# WS63 register map
File version: 1.0
CPU: other r0p0, little endian, MPU, FPU, 3 interrupt priority bits
Registers are 32-bit, read-write, reset 0x0 unless marked. A register's access mark holds for its fields unless they carry their own. Offsets are from the block's base; [hi:lo] are bit positions; {n}, {i} and the like mark numbered series.

## IO_CONFIG — IO multiplexing and pad control
Base 0x4400D000
0x00 GPIO_00_SEL — GPIO_00 pin mux select
  [2:0] gpio_00_sel — GPIO_00 pin mux: 0:GPIO_00; 1:PWM0; 2:DIAG[0]; 3:SPI1_CSN; 4:JTAG_TDI
0x04 GPIO_01_SEL — GPIO_01 pin mux select
  [2:0] gpio_01_sel — GPIO_01 pin mux: 0:GPIO_01; 1:PWM1; 2:DIAG[1]; 3:SPI1_IO0; 4:JTAG_MODE; 5:BT_SAMPLE
0x08 GPIO_02_SEL — GPIO_02 pin mux select
  [2:0] gpio_02_sel — GPIO_02 pin mux: 0:GPIO_02; 1:PWM2; 2:DIAG[2]; 3:SPI1_IO3; 4:WIFI_TSF_SYNC; 5:WL_GLP_SYNC_PULSE; 6:BSLE_GLP_SYNC_PULSE
0x0C GPIO_03_SEL — GPIO_03 pin mux select
  [2:0] gpio_03_sel — GPIO_03 pin mux: 0:GPIO_03; 1:PWM3; 2:PMU_32K_TEST; 3:SPI1_IO1; 4:HW_ID[0]; 5:DIAG[3]
0x10 GPIO_04_SEL — GPIO_04 pin mux select
  [2:0] gpio_04_sel — GPIO_04 pin mux: 0:SSI_CLK; 1:PWM4; 2:GPIO_04; 3:SPI1_IO1; 4:JTAG_ENABLE; 5:DFT_JTAG_TMS
0x14 GPIO_05_SEL — GPIO_05 pin mux select
  [2:0] gpio_05_sel — GPIO_05 pin mux: 0:SSI_DATA; 1:PWM5; 2:UART2_CTS; 3:SPI1_IO2; 4:GPIO_05; 5:SPI0_IN; 6:DFT_JTAG_TCK
0x18 GPIO_06_SEL — GPIO_06 pin mux select
  [2:0] gpio_06_sel — GPIO_06 pin mux: 0:GPIO_06; 1:PWM6; 2:UART2_RTS; 3:SPI1_SCK; 4:REFCLK_FREQ_STATUS; 5:DIAG[4]; 6:SPI0_OUT; 7:DFT_JTAG_TDI
0x1C GPIO_07_SEL — GPIO_07 pin mux select
  [2:0] gpio_07_sel — GPIO_07 pin mux: 0:GPIO_07; 1:PWM7; 2:UART2_RXD; 3:SPI0_SCK; 4:I2S_MCLK; 5:DIAG[5]
0x20 GPIO_08_SEL — GPIO_08 pin mux select
  [2:0] gpio_08_sel — GPIO_08 pin mux: 0:GPIO_08; 1:PWM0; 2:UART2_TXD; 3:SPI0_CS1_N; 4:DIAG[6]
0x24 GPIO_09_SEL — GPIO_09 pin mux select
  [2:0] gpio_09_sel — GPIO_09 pin mux: 0:GPIO_09; 1:PWM1; 2:RADAR_ANT0_SW; 3:SPI0_OUT; 4:I2S_DO; 5:HW_ID[1]; 6:DIAG[7]; 7:JTAG_TDO
0x28 GPIO_10_SEL — GPIO_10 pin mux select
  [2:0] gpio_10_sel — GPIO_10 pin mux: 0:GPIO_10; 1:PWM2; 2:ANT0_SW; 3:SPI0_CS0_N; 4:I2S_SCLK; 5:DIAG[0]
0x2C GPIO_11_SEL — GPIO_11 pin mux select
  [2:0] gpio_11_sel — GPIO_11 pin mux: 0:GPIO_11; 1:PWM3; 2:RADAR_ANT1_SW; 3:SPI0_IN; 4:I2S_LRCLK; 5:DIAG[1]; 6:HW_ID[2]
0x30 GPIO_12_SEL — GPIO_12 pin mux select
  [2:0] gpio_12_sel — GPIO_12 pin mux: 0:GPIO_12; 1:PWM4; 2:ANT1_SW; 4:I2S_DI; 6:HW_ID[3]
0x34 GPIO_13_SEL — GPIO_13 pin mux select
  [2:0] gpio_13_sel — GPIO_13 pin mux: 0:GPIO_13; 1:UART1_CTS; 2:RADAR_ANT0_SW; 3:DFT_JTAG_TDO; 4:JTAG_TMS
0x38 GPIO_14_SEL — GPIO_14 pin mux select
  [2:0] gpio_14_sel — GPIO_14 pin mux: 0:GPIO_14; 1:UART1_RTS; 2:RADAR_ANT1_SW; 3:DFT_JTAG_TRSTN; 4:JTAG_TCK
0x3C UART1_TXD_SEL — UART1_TXD pin mux select
  [1:0] uart1_txd_sel — UART1_TXD pin mux: 0:GPIO_15; 1:UART1_TXD; 2:I2C1_SDA
0x40 UART1_RXD_SEL — UART1_RXD pin mux select
  [1:0] uart1_rxd_sel — UART1_RXD pin mux: 0:GPIO_16; 1:UART1_RXD; 2:I2C1_SCL
0x44 UART0_TXD_SEL — UART0_TXD pin mux select
  [1:0] uart0_txd_sel — UART0_TXD pin mux: 0:GPIO_17; 1:UART0_TXD; 2:I2C0_SDA
0x48 UART0_RXD_SEL — UART0_RXD pin mux select
  [1:0] uart0_rxd_sel — UART0_RXD pin mux: 0:GPIO_18; 1:UART0_RXD; 2:I2C0_SCL
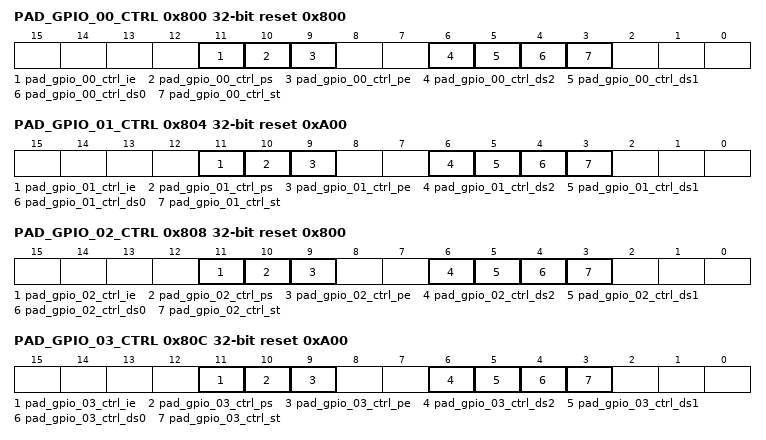
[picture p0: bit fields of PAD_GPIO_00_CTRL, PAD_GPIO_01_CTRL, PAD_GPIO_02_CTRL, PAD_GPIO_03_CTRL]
0x800 PAD_GPIO_00_CTRL reset 0x800 — GPIO_00 pad control register
  [11] pad_gpio_00_ctrl_ie — Input enable: 0:input disabled; 1:input enabled
  [10] pad_gpio_00_ctrl_ps — Pull select. PE/PS: 00:no pull; 01:strong pull-up; 10:pull-down; 11:pull-up
  [9] pad_gpio_00_ctrl_pe — Pull enable. PE/PS: 00:no pull; 01:strong pull-up; 10:pull-down; 11:pull-up
  [6] pad_gpio_00_ctrl_ds2 — Drive strength bit 2. DS2~DS0: 111~000, drive strength decreases
  [5] pad_gpio_00_ctrl_ds1 — Drive strength bit 1
  [4] pad_gpio_00_ctrl_ds0 — Drive strength bit 0
  [3] pad_gpio_00_ctrl_st — Schmitt trigger: 0:No Schmitt; 1:Schmitt Enable
0x804 PAD_GPIO_01_CTRL reset 0xA00 — GPIO_01 pad control register
  [11] pad_gpio_01_ctrl_ie — Input enable
  [10] pad_gpio_01_ctrl_ps — Pull select
  [9] pad_gpio_01_ctrl_pe — Pull enable
  [6] pad_gpio_01_ctrl_ds2 — Drive strength bit 2
  [5] pad_gpio_01_ctrl_ds1 — Drive strength bit 1
  [4] pad_gpio_01_ctrl_ds0 — Drive strength bit 0
  [3] pad_gpio_01_ctrl_st — Schmitt trigger: 0:No Schmitt; 1:Schmitt Enable
0x808 PAD_GPIO_02_CTRL reset 0x800 — GPIO_02 pad control register
  [11] pad_gpio_02_ctrl_ie — Input enable
  [10] pad_gpio_02_ctrl_ps — Pull select
  [9] pad_gpio_02_ctrl_pe — Pull enable
  [6] pad_gpio_02_ctrl_ds2 — Drive strength bit 2
  [5] pad_gpio_02_ctrl_ds1 — Drive strength bit 1
  [4] pad_gpio_02_ctrl_ds0 — Drive strength bit 0
  [3] pad_gpio_02_ctrl_st — Schmitt trigger
0x80C PAD_GPIO_03_CTRL reset 0xA00 — GPIO_03 pad control register
  [11] pad_gpio_03_ctrl_ie — Input enable
  [10] pad_gpio_03_ctrl_ps — Pull select
  [9] pad_gpio_03_ctrl_pe — Pull enable
  [6] pad_gpio_03_ctrl_ds2 — Drive strength bit 2
  [5] pad_gpio_03_ctrl_ds1 — Drive strength bit 1
  [4] pad_gpio_03_ctrl_ds0 — Drive strength bit 0
  [3] pad_gpio_03_ctrl_st — Schmitt trigger
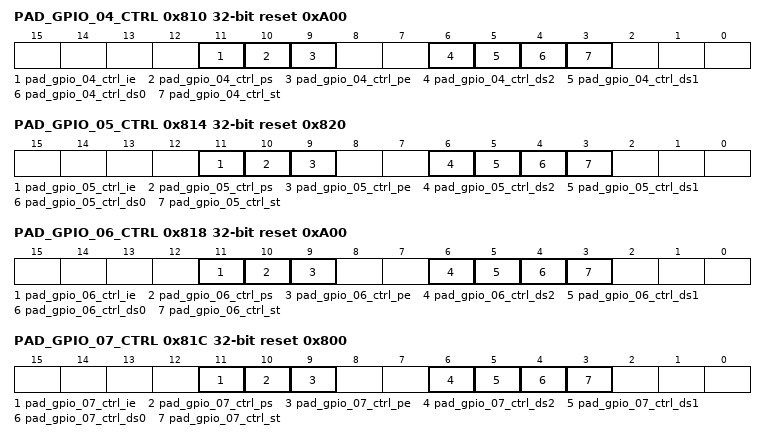
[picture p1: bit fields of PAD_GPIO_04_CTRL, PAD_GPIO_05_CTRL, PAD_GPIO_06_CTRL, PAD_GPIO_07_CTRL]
0x810 PAD_GPIO_04_CTRL reset 0xA00 — GPIO_04 pad control register
  [11] pad_gpio_04_ctrl_ie — Input enable
  [10] pad_gpio_04_ctrl_ps — Pull select
  [9] pad_gpio_04_ctrl_pe — Pull enable
  [6] pad_gpio_04_ctrl_ds2 — Drive strength bit 2
  [5] pad_gpio_04_ctrl_ds1 — Drive strength bit 1
  [4] pad_gpio_04_ctrl_ds0 — Drive strength bit 0
  [3] pad_gpio_04_ctrl_st — Schmitt trigger
0x814 PAD_GPIO_05_CTRL reset 0x820 — GPIO_05 pad control register
  [11] pad_gpio_05_ctrl_ie — Input enable
  [10] pad_gpio_05_ctrl_ps — Pull select
  [9] pad_gpio_05_ctrl_pe — Pull enable
  [6] pad_gpio_05_ctrl_ds2 — Drive strength bit 2
  [5] pad_gpio_05_ctrl_ds1 — Drive strength bit 1
  [4] pad_gpio_05_ctrl_ds0 — Drive strength bit 0
  [3] pad_gpio_05_ctrl_st — Schmitt trigger
0x818 PAD_GPIO_06_CTRL reset 0xA00 — GPIO_06 pad control register
  [11] pad_gpio_06_ctrl_ie — Input enable
  [10] pad_gpio_06_ctrl_ps — Pull select
  [9] pad_gpio_06_ctrl_pe — Pull enable
  [6] pad_gpio_06_ctrl_ds2 — Drive strength bit 2
  [5] pad_gpio_06_ctrl_ds1 — Drive strength bit 1
  [4] pad_gpio_06_ctrl_ds0 — Drive strength bit 0
  [3] pad_gpio_06_ctrl_st — Schmitt trigger
0x81C PAD_GPIO_07_CTRL reset 0x800 — GPIO_07 pad control register
  [11] pad_gpio_07_ctrl_ie — Input enable
  [10] pad_gpio_07_ctrl_ps — Pull select
  [9] pad_gpio_07_ctrl_pe — Pull enable
  [6] pad_gpio_07_ctrl_ds2 — Drive strength bit 2
  [5] pad_gpio_07_ctrl_ds1 — Drive strength bit 1
  [4] pad_gpio_07_ctrl_ds0 — Drive strength bit 0
  [3] pad_gpio_07_ctrl_st — Schmitt trigger
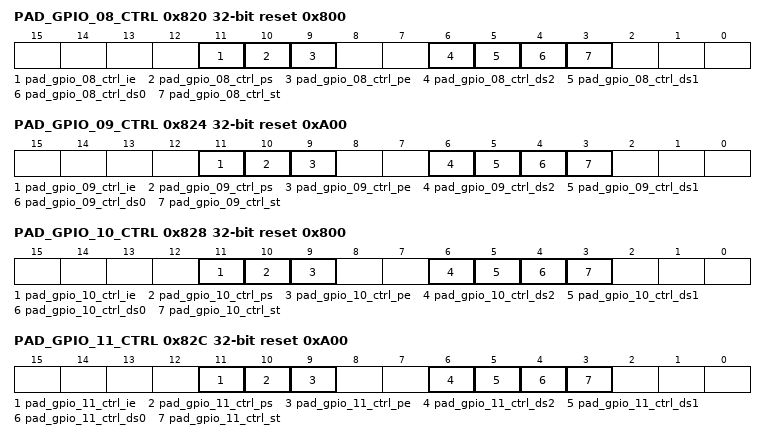
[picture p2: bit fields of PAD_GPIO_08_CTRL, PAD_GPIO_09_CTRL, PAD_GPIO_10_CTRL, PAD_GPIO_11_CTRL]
0x820 PAD_GPIO_08_CTRL reset 0x800 — GPIO_08 pad control register
  [11] pad_gpio_08_ctrl_ie — Input enable
  [10] pad_gpio_08_ctrl_ps — Pull select
  [9] pad_gpio_08_ctrl_pe — Pull enable
  [6] pad_gpio_08_ctrl_ds2 — Drive strength bit 2
  [5] pad_gpio_08_ctrl_ds1 — Drive strength bit 1
  [4] pad_gpio_08_ctrl_ds0 — Drive strength bit 0
  [3] pad_gpio_08_ctrl_st — Schmitt trigger
0x824 PAD_GPIO_09_CTRL reset 0xA00 — GPIO_09 pad control register
  [11] pad_gpio_09_ctrl_ie — Input enable
  [10] pad_gpio_09_ctrl_ps — Pull select
  [9] pad_gpio_09_ctrl_pe — Pull enable
  [6] pad_gpio_09_ctrl_ds2 — Drive strength bit 2
  [5] pad_gpio_09_ctrl_ds1 — Drive strength bit 1
  [4] pad_gpio_09_ctrl_ds0 — Drive strength bit 0
  [3] pad_gpio_09_ctrl_st — Schmitt trigger
0x828 PAD_GPIO_10_CTRL reset 0x800 — GPIO_10 pad control register
  [11] pad_gpio_10_ctrl_ie — Input enable
  [10] pad_gpio_10_ctrl_ps — Pull select
  [9] pad_gpio_10_ctrl_pe — Pull enable
  [6] pad_gpio_10_ctrl_ds2 — Drive strength bit 2
  [5] pad_gpio_10_ctrl_ds1 — Drive strength bit 1
  [4] pad_gpio_10_ctrl_ds0 — Drive strength bit 0
  [3] pad_gpio_10_ctrl_st — Schmitt trigger
0x82C PAD_GPIO_11_CTRL reset 0xA00 — GPIO_11 pad control register
  [11] pad_gpio_11_ctrl_ie — Input enable
  [10] pad_gpio_11_ctrl_ps — Pull select
  [9] pad_gpio_11_ctrl_pe — Pull enable
  [6] pad_gpio_11_ctrl_ds2 — Drive strength bit 2
  [5] pad_gpio_11_ctrl_ds1 — Drive strength bit 1
  [4] pad_gpio_11_ctrl_ds0 — Drive strength bit 0
  [3] pad_gpio_11_ctrl_st — Schmitt trigger
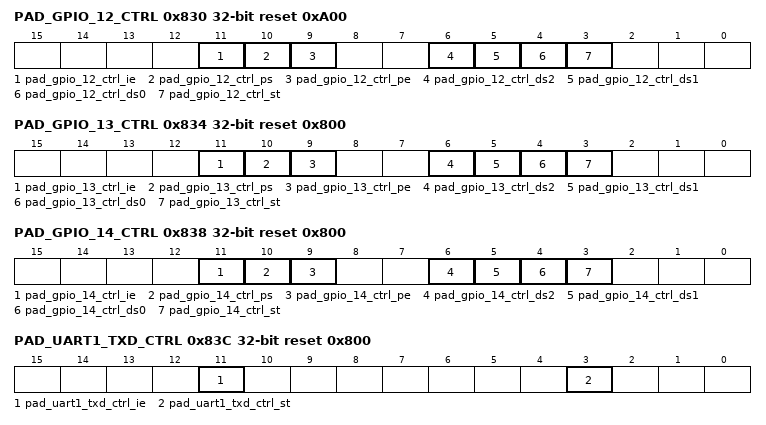
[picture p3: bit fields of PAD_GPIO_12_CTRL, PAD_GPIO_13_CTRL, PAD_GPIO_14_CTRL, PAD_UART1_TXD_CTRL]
0x830 PAD_GPIO_12_CTRL reset 0xA00 — GPIO_12 pad control register
  [11] pad_gpio_12_ctrl_ie — Input enable
  [10] pad_gpio_12_ctrl_ps — Pull select
  [9] pad_gpio_12_ctrl_pe — Pull enable
  [6] pad_gpio_12_ctrl_ds2 — Drive strength bit 2
  [5] pad_gpio_12_ctrl_ds1 — Drive strength bit 1
  [4] pad_gpio_12_ctrl_ds0 — Drive strength bit 0
  [3] pad_gpio_12_ctrl_st — Schmitt trigger
0x834 PAD_GPIO_13_CTRL reset 0x800 — GPIO_13 pad control register
  [11] pad_gpio_13_ctrl_ie — Input enable
  [10] pad_gpio_13_ctrl_ps — Pull select
  [9] pad_gpio_13_ctrl_pe — Pull enable
  [6] pad_gpio_13_ctrl_ds2 — Drive strength bit 2
  [5] pad_gpio_13_ctrl_ds1 — Drive strength bit 1
  [4] pad_gpio_13_ctrl_ds0 — Drive strength bit 0
  [3] pad_gpio_13_ctrl_st — Schmitt trigger
0x838 PAD_GPIO_14_CTRL reset 0x800 — GPIO_14 pad control register
  [11] pad_gpio_14_ctrl_ie — Input enable
  [10] pad_gpio_14_ctrl_ps — Pull select
  [9] pad_gpio_14_ctrl_pe — Pull enable
  [6] pad_gpio_14_ctrl_ds2 — Drive strength bit 2
  [5] pad_gpio_14_ctrl_ds1 — Drive strength bit 1
  [4] pad_gpio_14_ctrl_ds0 — Drive strength bit 0
  [3] pad_gpio_14_ctrl_st — Schmitt trigger
0x83C PAD_UART1_TXD_CTRL reset 0x800 — UART1_TXD pad control register
  [11] pad_uart1_txd_ctrl_ie — Input enable
  [3] pad_uart1_txd_ctrl_st — Schmitt trigger
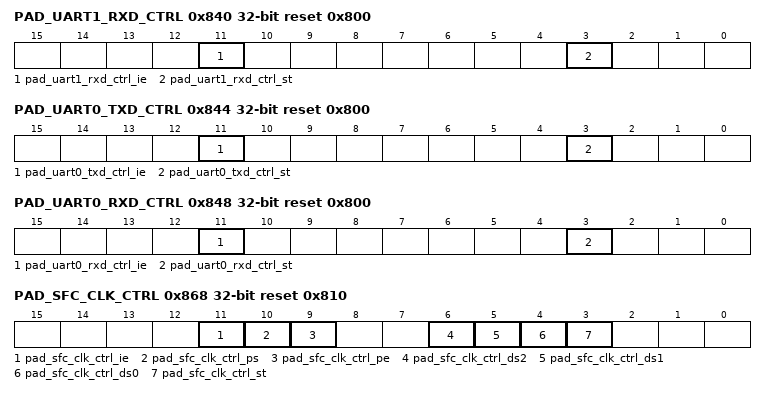
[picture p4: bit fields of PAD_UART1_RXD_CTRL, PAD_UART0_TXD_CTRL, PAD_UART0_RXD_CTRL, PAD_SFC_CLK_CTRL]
0x840 PAD_UART1_RXD_CTRL reset 0x800 — UART1_RXD pad control register
  [11] pad_uart1_rxd_ctrl_ie — Input enable
  [3] pad_uart1_rxd_ctrl_st — Schmitt trigger
0x844 PAD_UART0_TXD_CTRL reset 0x800 — UART0_TXD pad control register
  [11] pad_uart0_txd_ctrl_ie — Input enable
  [3] pad_uart0_txd_ctrl_st — Schmitt trigger
0x848 PAD_UART0_RXD_CTRL reset 0x800 — UART0_RXD pad control register
  [11] pad_uart0_rxd_ctrl_ie — Input enable
  [3] pad_uart0_rxd_ctrl_st — Schmitt trigger
0x868 PAD_SFC_CLK_CTRL reset 0x810 — SFC_CLK pad control register
  [11] pad_sfc_clk_ctrl_ie — Input enable
  [10] pad_sfc_clk_ctrl_ps — Pull select
  [9] pad_sfc_clk_ctrl_pe — Pull enable
  [6] pad_sfc_clk_ctrl_ds2 — Drive strength bit 2
  [5] pad_sfc_clk_ctrl_ds1 — Drive strength bit 1
  [4] pad_sfc_clk_ctrl_ds0 — Drive strength bit 0
  [3] pad_sfc_clk_ctrl_st — Schmitt trigger
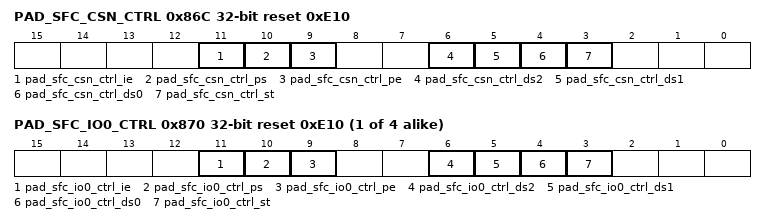
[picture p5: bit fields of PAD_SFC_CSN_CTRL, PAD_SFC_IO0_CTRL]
0x86C PAD_SFC_CSN_CTRL reset 0xE10 — SFC_CSN pad control register
  [11] pad_sfc_csn_ctrl_ie — Input enable
  [10] pad_sfc_csn_ctrl_ps — Pull select
  [9] pad_sfc_csn_ctrl_pe — Pull enable
  [6] pad_sfc_csn_ctrl_ds2 — Drive strength bit 2
  [5] pad_sfc_csn_ctrl_ds1 — Drive strength bit 1
  [4] pad_sfc_csn_ctrl_ds0 — Drive strength bit 0
  [3] pad_sfc_csn_ctrl_st — Schmitt trigger
{0x870+4i} PAD_SFC_IO{i}_CTRL reset 0xE10 (i=0..3) — SFC_IO{i} pad control register
  [11] pad_sfc_io{i}_ctrl_ie — Input enable
  [10] pad_sfc_io{i}_ctrl_ps — Pull select
  [9] pad_sfc_io{i}_ctrl_pe — Pull enable
  [6] pad_sfc_io{i}_ctrl_ds2 — Drive strength bit 2
  [5] pad_sfc_io{i}_ctrl_ds1 — Drive strength bit 1
  [4] pad_sfc_io{i}_ctrl_ds0 — Drive strength bit 0
  [3] pad_sfc_io{i}_ctrl_st — Schmitt trigger
